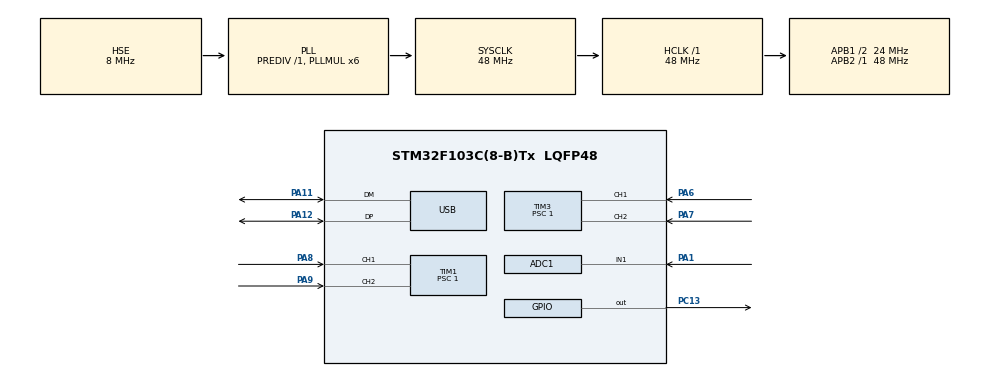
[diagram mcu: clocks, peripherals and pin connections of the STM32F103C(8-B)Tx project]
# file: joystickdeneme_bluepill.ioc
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ADC1.Channel-1\#ChannelRegularConversion=ADC_CHANNEL_1
ADC1.ContinuousConvMode=ENABLE
ADC1.DataAlign=ADC_DATAALIGN_RIGHT
ADC1.EnableInjectedConversion=DISABLE
ADC1.EnableRegularConversion=ENABLE
ADC1.NbrOfConversion=1
ADC1.NbrOfConversionFlag=1
ADC1.Rank-1\#ChannelRegularConversion=1
ADC1.SamplingTime-1\#ChannelRegularConversion=ADC_SAMPLETIME_1CYCLE_5
ADC1.master=1
Mcu.Family=STM32F1
Mcu.Name=STM32F103C(8-B)Tx
Mcu.Package=LQFP48
NVIC.PriorityGroup=NVIC_PRIORITYGROUP_4
NVIC.USB_LP_CAN1_RX0_IRQn=true\:0\:0\:false\:false\:true\:false\:true\:true
PA0-WKUP.Signal=ADCx_IN0
PA1.Signal=ADCx_IN1
PA11.Mode=Device
PA11.Signal=USB_DM
PA12.Mode=Device
PA12.Signal=USB_DP
PA13.Mode=Serial_Wire
PA13.Signal=SYS_JTMS-SWDIO
PA14.Mode=Serial_Wire
PA14.Signal=SYS_JTCK-SWCLK
PA6.Signal=S_TIM3_CH1
PA7.Signal=S_TIM3_CH2
PA8.Signal=S_TIM1_CH1
PA9.Signal=S_TIM1_CH2
PC13-TAMPER-RTC.Signal=GPIO_Output
PD0-OSC_IN.Mode=HSE-External-Oscillator
PD0-OSC_IN.Signal=RCC_OSC_IN
PD1-OSC_OUT.Mode=HSE-External-Oscillator
PD1-OSC_OUT.Signal=RCC_OSC_OUT
ProjectManager.HeapSize=0x200
ProjectManager.StackSize=0x400
ProjectManager.TargetToolchain=STM32CubeIDE
RCC.ADCPresc=RCC_ADCPCLK2_DIV4
RCC.AHBFreq_Value=48000000
RCC.APB1CLKDivider=RCC_HCLK_DIV2
RCC.APB1Freq_Value=24000000
RCC.APB1TimFreq_Value=48000000
RCC.APB2Freq_Value=48000000
RCC.APB2TimFreq_Value=48000000
RCC.HCLKFreq_Value=48000000
RCC.PLLMUL=RCC_PLL_MUL6
RCC.PLLSourceVirtual=RCC_PLLSOURCE_HSE
RCC.SYSCLKFreq_VALUE=48000000
RCC.SYSCLKSource=RCC_SYSCLKSOURCE_PLLCLK
RCC.USBFreq_Value=48000000
SH.ADCx_IN0.0=ADC1_IN0
SH.ADCx_IN1.0=ADC1_IN1,IN1
SH.S_TIM1_CH1.0=TIM1_CH1,Encoder_Interface
SH.S_TIM1_CH2.0=TIM1_CH2,Encoder_Interface
SH.S_TIM3_CH1.0=TIM3_CH1,Encoder_Interface
SH.S_TIM3_CH2.0=TIM3_CH2,Encoder_Interface
TIM1.AutoReloadPreload=TIM_AUTORELOAD_PRELOAD_ENABLE
TIM1.EncoderMode=TIM_ENCODERMODE_TI12
TIM1.IC1Filter=12
TIM1.IC2Filter=12
TIM1.Period=99
TIM1.Prescaler=1
TIM3.AutoReloadPreload=TIM_AUTORELOAD_PRELOAD_ENABLE
TIM3.EncoderMode=TIM_ENCODERMODE_TI12
TIM3.IC1Filter=12
TIM3.IC2Filter=12
TIM3.Period=99
TIM3.Prescaler=1
USB_DEVICE.CLASS_NAME_FS=CDC
USB_DEVICE.VirtualMode=Cdc
USB_DEVICE.VirtualModeFS=Cdc_FS
VP_USB_DEVICE_VS_USB_DEVICE_CDC_FS.Mode=CDC_FS
board=custom

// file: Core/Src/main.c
/* USER CODE BEGIN Header */
/**
  ******************************************************************************
  * @file           : main.c
  * @brief          : Main program body
  ******************************************************************************
  * @attention
  *
  * Copyright (c) 2024 STMicroelectronics.
  * All rights reserved.
  *
  * This software is licensed under terms that can be found in the LICENSE file
  * in the root directory of this software component.
  * If no LICENSE file comes with this software, it is provided AS-IS.
  *
  ******************************************************************************
  */
/* USER CODE END Header */
#include "main.h"
#include "usb_device.h"

ADC_HandleTypeDef hadc1;

TIM_HandleTypeDef htim1;
TIM_HandleTypeDef htim3;

/* USER CODE BEGIN PV */
uint32_t encoder1_value;
uint32_t encoder2_value;
uint32_t pot;

char encoder_buffer[800]={'\0'};
/* USER CODE END PV */

void SystemClock_Config(void);
static void MX_GPIO_Init(void);
static void MX_TIM3_Init(void);
static void MX_TIM1_Init(void);
static void MX_ADC1_Init(void);

int main(void)
{

  /* MCU Configuration--------------------------------------------------------*/

  /* Reset of all peripherals, Initializes the Flash interface and the Systick. */
  HAL_Init();

  /* Configure the system clock */
  SystemClock_Config();

  /* Initialize all configured peripherals */
  MX_GPIO_Init();
  MX_TIM3_Init();
  MX_TIM1_Init();
  MX_USB_DEVICE_Init();
  MX_ADC1_Init();
  /* USER CODE BEGIN 2 */
	HAL_TIM_Base_Start_IT(&htim3);
	HAL_TIM_Base_Start_IT(&htim1);

	HAL_TIM_Encoder_Start_IT(&htim3, TIM_CHANNEL_ALL);
	HAL_TIM_Encoder_Start_IT(&htim1, TIM_CHANNEL_ALL);
  /* USER CODE END 2 */

  /* Infinite loop */
  /* USER CODE BEGIN WHILE */
  while (1)
  {

	  encoder1_value = TIM3->CNT;
	  encoder2_value = TIM1->CNT;

	  sprintf(encoder_buffer, "%d %d\n\r", encoder1_value, encoder2_value);
	  CDC_Transmit_FS(encoder_buffer, strlen(encoder_buffer));
	  HAL_Delay(50);

	  /*HAL_UART_Transmit(&huart1, (uint8_t*)encoder_buffer, sizeof(encoder_buffer), 300);*/

	  /*
	  sprintf(encoder_buffer, "first encoder: %d\n\r", ((TIM3->CNT)>>3));
	  CDC_Transmit_FS((uint8_t*)encoder_buffer, strlen(encoder_buffer));
	  HAL_Delay(500);*/

    /* USER CODE END WHILE */

  }
}

void SystemClock_Config(void)
{
  RCC_OscInitTypeDef RCC_OscInitStruct = {0};
  RCC_ClkInitTypeDef RCC_ClkInitStruct = {0};
  RCC_PeriphCLKInitTypeDef PeriphClkInit = {0};

  /** Initializes the RCC Oscillators according to the specified parameters
  * in the RCC_OscInitTypeDef structure.
  */
  RCC_OscInitStruct.OscillatorType = RCC_OSCILLATORTYPE_HSE;
  RCC_OscInitStruct.HSEState = RCC_HSE_ON;
  RCC_OscInitStruct.HSEPredivValue = RCC_HSE_PREDIV_DIV1;
  RCC_OscInitStruct.HSIState = RCC_HSI_ON;
  RCC_OscInitStruct.PLL.PLLState = RCC_PLL_ON;
  RCC_OscInitStruct.PLL.PLLSource = RCC_PLLSOURCE_HSE;
  RCC_OscInitStruct.PLL.PLLMUL = RCC_PLL_MUL6;
  if (HAL_RCC_OscConfig(&RCC_OscInitStruct) != HAL_OK)
  {
    Error_Handler();
  }

  /** Initializes the CPU, AHB and APB buses clocks
  */
  RCC_ClkInitStruct.ClockType = RCC_CLOCKTYPE_HCLK|RCC_CLOCKTYPE_SYSCLK
                              |RCC_CLOCKTYPE_PCLK1|RCC_CLOCKTYPE_PCLK2;
  RCC_ClkInitStruct.SYSCLKSource = RCC_SYSCLKSOURCE_PLLCLK;
  RCC_ClkInitStruct.AHBCLKDivider = RCC_SYSCLK_DIV1;
  RCC_ClkInitStruct.APB1CLKDivider = RCC_HCLK_DIV2;
  RCC_ClkInitStruct.APB2CLKDivider = RCC_HCLK_DIV1;

  if (HAL_RCC_ClockConfig(&RCC_ClkInitStruct, FLASH_LATENCY_1) != HAL_OK)
  {
    Error_Handler();
  }
  PeriphClkInit.PeriphClockSelection = RCC_PERIPHCLK_ADC|RCC_PERIPHCLK_USB;
  PeriphClkInit.AdcClockSelection = RCC_ADCPCLK2_DIV4;
  PeriphClkInit.UsbClockSelection = RCC_USBCLKSOURCE_PLL;
  if (HAL_RCCEx_PeriphCLKConfig(&PeriphClkInit) != HAL_OK)
  {
    Error_Handler();
  }
}

static void MX_ADC1_Init(void)
{

  ADC_ChannelConfTypeDef sConfig = {0};

  /** Common config
  */
  hadc1.Instance = ADC1;
  hadc1.Init.ScanConvMode = ADC_SCAN_DISABLE;
  hadc1.Init.ContinuousConvMode = ENABLE;
  hadc1.Init.DiscontinuousConvMode = DISABLE;
  hadc1.Init.ExternalTrigConv = ADC_SOFTWARE_START;
  hadc1.Init.DataAlign = ADC_DATAALIGN_RIGHT;
  hadc1.Init.NbrOfConversion = 1;
  if (HAL_ADC_Init(&hadc1) != HAL_OK)
  {
    Error_Handler();
  }

  /** Configure Regular Channel
  */
  sConfig.Channel = ADC_CHANNEL_1;
  sConfig.Rank = ADC_REGULAR_RANK_1;
  sConfig.SamplingTime = ADC_SAMPLETIME_1CYCLE_5;
  if (HAL_ADC_ConfigChannel(&hadc1, &sConfig) != HAL_OK)
  {
    Error_Handler();
  }

}

static void MX_TIM1_Init(void)
{

  TIM_Encoder_InitTypeDef sConfig = {0};
  TIM_MasterConfigTypeDef sMasterConfig = {0};

  htim1.Instance = TIM1;
  htim1.Init.Prescaler = 1;
  htim1.Init.CounterMode = TIM_COUNTERMODE_UP;
  htim1.Init.Period = 99;
  htim1.Init.ClockDivision = TIM_CLOCKDIVISION_DIV1;
  htim1.Init.RepetitionCounter = 0;
  htim1.Init.AutoReloadPreload = TIM_AUTORELOAD_PRELOAD_ENABLE;
  sConfig.EncoderMode = TIM_ENCODERMODE_TI12;
  sConfig.IC1Polarity = TIM_ICPOLARITY_RISING;
  sConfig.IC1Selection = TIM_ICSELECTION_DIRECTTI;
  sConfig.IC1Prescaler = TIM_ICPSC_DIV1;
  sConfig.IC1Filter = 12;
  sConfig.IC2Polarity = TIM_ICPOLARITY_RISING;
  sConfig.IC2Selection = TIM_ICSELECTION_DIRECTTI;
  sConfig.IC2Prescaler = TIM_ICPSC_DIV1;
  sConfig.IC2Filter = 12;
  if (HAL_TIM_Encoder_Init(&htim1, &sConfig) != HAL_OK)
  {
    Error_Handler();
  }
  sMasterConfig.MasterOutputTrigger = TIM_TRGO_RESET;
  sMasterConfig.MasterSlaveMode = TIM_MASTERSLAVEMODE_DISABLE;
  if (HAL_TIMEx_MasterConfigSynchronization(&htim1, &sMasterConfig) != HAL_OK)
  {
    Error_Handler();
  }

}

static void MX_TIM3_Init(void)
{

  TIM_Encoder_InitTypeDef sConfig = {0};
  TIM_MasterConfigTypeDef sMasterConfig = {0};

  htim3.Instance = TIM3;
  htim3.Init.Prescaler = 1;
  htim3.Init.CounterMode = TIM_COUNTERMODE_UP;
  htim3.Init.Period = 99;
  htim3.Init.ClockDivision = TIM_CLOCKDIVISION_DIV1;
  htim3.Init.AutoReloadPreload = TIM_AUTORELOAD_PRELOAD_ENABLE;
  sConfig.EncoderMode = TIM_ENCODERMODE_TI12;
  sConfig.IC1Polarity = TIM_ICPOLARITY_RISING;
  sConfig.IC1Selection = TIM_ICSELECTION_DIRECTTI;
  sConfig.IC1Prescaler = TIM_ICPSC_DIV1;
  sConfig.IC1Filter = 12;
  sConfig.IC2Polarity = TIM_ICPOLARITY_RISING;
  sConfig.IC2Selection = TIM_ICSELECTION_DIRECTTI;
  sConfig.IC2Prescaler = TIM_ICPSC_DIV1;
  sConfig.IC2Filter = 12;
  if (HAL_TIM_Encoder_Init(&htim3, &sConfig) != HAL_OK)
  {
    Error_Handler();
  }
  sMasterConfig.MasterOutputTrigger = TIM_TRGO_RESET;
  sMasterConfig.MasterSlaveMode = TIM_MASTERSLAVEMODE_DISABLE;
  if (HAL_TIMEx_MasterConfigSynchronization(&htim3, &sMasterConfig) != HAL_OK)
  {
    Error_Handler();
  }

}

static void MX_GPIO_Init(void)
{
  GPIO_InitTypeDef GPIO_InitStruct = {0};

  /* GPIO Ports Clock Enable */
  __HAL_RCC_GPIOC_CLK_ENABLE();
  __HAL_RCC_GPIOD_CLK_ENABLE();
  __HAL_RCC_GPIOA_CLK_ENABLE();

  /*Configure GPIO pin Output Level */
  HAL_GPIO_WritePin(GPIOC, GPIO_PIN_13, GPIO_PIN_RESET);

  /*Configure GPIO pin : PC13 */
  GPIO_InitStruct.Pin = GPIO_PIN_13;
  GPIO_InitStruct.Mode = GPIO_MODE_OUTPUT_PP;
  GPIO_InitStruct.Pull = GPIO_NOPULL;
  GPIO_InitStruct.Speed = GPIO_SPEED_FREQ_LOW;
  HAL_GPIO_Init(GPIOC, &GPIO_InitStruct);

}

void Error_Handler(void)
{
  __disable_irq();
  while (1)
  {
  }
}
